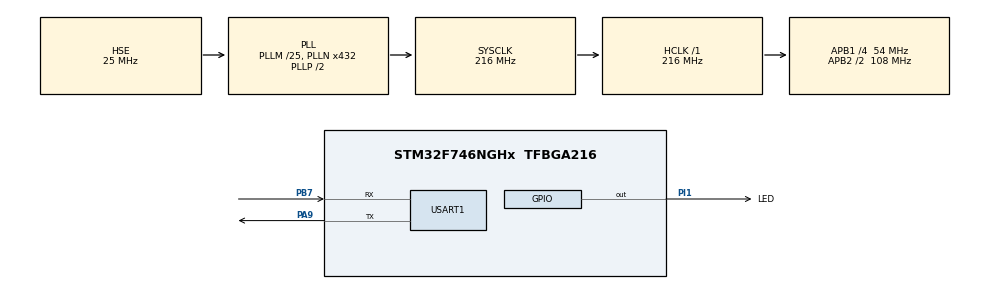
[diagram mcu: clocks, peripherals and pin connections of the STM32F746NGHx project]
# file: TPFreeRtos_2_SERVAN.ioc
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FREERTOS.Tasks01=defaultTask,0,128,StartDefaultTask,Default,NULL,Dynamic,NULL,NULL
FREERTOS.configTOTAL_HEAP_SIZE=20000
FREERTOS.configUSE_NEWLIB_REENTRANT=1
Mcu.Family=STM32F7
Mcu.Name=STM32F746NGHx
Mcu.Package=TFBGA216
NVIC.PriorityGroup=NVIC_PRIORITYGROUP_4
NVIC.TIM6_DAC_IRQn=true\:15\:0\:false\:false\:true\:false\:false\:true\:true
NVIC.TimeBase=TIM6_DAC_IRQn
NVIC.TimeBaseIP=TIM6
NVIC.USART1_IRQn=true\:5\:0\:false\:false\:true\:true\:true\:true\:true
PA13.Mode=Serial_Wire
PA13.Signal=SYS_JTMS-SWDIO
PA14.Mode=Serial_Wire
PA14.Signal=SYS_JTCK-SWCLK
PA9.Mode=Asynchronous
PA9.Signal=USART1_TX
PB7.Mode=Asynchronous
PB7.Signal=USART1_RX
PH0/OSC_IN.Mode=HSE-External-Oscillator
PH0/OSC_IN.Signal=RCC_OSC_IN
PH1/OSC_OUT.Mode=HSE-External-Oscillator
PH1/OSC_OUT.Signal=RCC_OSC_OUT
PI1.GPIO_Label=LED
PI1.Signal=GPIO_Output
ProjectManager.HeapSize=0x200
ProjectManager.StackSize=0x400
ProjectManager.TargetToolchain=STM32CubeIDE
RCC.AHBFreq_Value=216000000
RCC.APB1CLKDivider=RCC_HCLK_DIV4
RCC.APB1Freq_Value=54000000
RCC.APB1TimFreq_Value=108000000
RCC.APB2CLKDivider=RCC_HCLK_DIV2
RCC.APB2Freq_Value=108000000
RCC.APB2TimFreq_Value=216000000
RCC.CortexFreq_Value=216000000
RCC.HCLKFreq_Value=216000000
RCC.HSE_VALUE=25000000
RCC.HSI_VALUE=16000000
RCC.LSE_VALUE=32768
RCC.PLLM=25
RCC.PLLN=432
RCC.PLLSourceVirtual=RCC_PLLSOURCE_HSE
RCC.SYSCLKFreq_VALUE=216000000
RCC.SYSCLKSource=RCC_SYSCLKSOURCE_PLLCLK
RCC.USBFreq_Value=216000000
RCC.VCOOutputFreq_Value=432000000
USART1.VirtualMode-Asynchronous=VM_ASYNC
VP_FREERTOS_VS_CMSIS_V1.Mode=CMSIS_V1
VP_SYS_VS_tim6.Mode=TIM6
board=STM32F746G-DISCO

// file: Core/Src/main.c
/* USER CODE BEGIN Header */
/**
 ******************************************************************************
 * @file           : main.c
 * @brief          : Main program body
 ******************************************************************************
 * @attention
 *
 * Copyright (c) 2023 STMicroelectronics.
 * All rights reserved.
 *
 * This software is licensed under terms that can be found in the LICENSE file
 * in the root directory of this software component.
 * If no LICENSE file comes with this software, it is provided AS-IS.
 *
 ******************************************************************************
 */
/* USER CODE END Header */
#include "main.h"
#include "cmsis_os.h"
#include "usart.h"
#include "gpio.h"

/* USER CODE BEGIN Includes */
#include <stdio.h>
#include <stdlib.h>
#include "shell.h"
/* USER CODE END Includes */

/* USER CODE BEGIN PD */
#define TASK_SHELL_STACK_LENGHT 512
#define TASK_SHELL_PRIORITY 1
/* USER CODE END PD */

void SystemClock_Config(void);
void MX_FREERTOS_Init(void);

/* USER CODE BEGIN 0 */
int __io_putchar(int ch)
{
	HAL_UART_Transmit(&huart1, (uint8_t*)&ch, 1, HAL_MAX_DELAY);

	return ch;
}

int fonction(int argc, char ** argv)
{
	for (int i=0;i<argc;i++)
	{
		printf("l'argument %d est : %s\r\n",i,argv[i]);
	}

	return 0;
}

int addition(int argc, char ** argv)
{
	if (argc ==3)
	{
		int a,b;

		a=atoi(argv[1]);
		b=atoi(argv[2]);
		printf("La somme est %d\r\n",a+b);
	}
	else
	{
		printf("Erreur, il n'y a pas le bon nombre d'argument\r\n");
	}
	return 0;
}

void HAL_UART_RxCpltCallback(UART_HandleTypeDef *huart){

	if(huart -> Instance == USART1)
	{
		shell_uart_receive_irq_cb();
	}
}

void task_shell(void * unused){
	shell_init();
	shell_add('f', fonction, "Une fonction inutile");
	shell_add('a', addition, "Une fonction qui fait la somme");
	shell_run();
	//shell run est une fct infinie on ne sort pas de la tache
}
/* USER CODE END 0 */

int main(void)
{

	/* MCU Configuration--------------------------------------------------------*/

	/* Reset of all peripherals, Initializes the Flash interface and the Systick. */
	HAL_Init();

	/* Configure the system clock */
	SystemClock_Config();

	/* Initialize all configured peripherals */
	MX_GPIO_Init();
	MX_USART1_UART_Init();
	/* USER CODE BEGIN 2 */
	BaseType_t ret;
	TaskHandle_t h_task_shell =NULL;

	ret = xTaskCreate(task_shell, "Shell", TASK_SHELL_STACK_LENGHT, NULL, TASK_SHELL_PRIORITY, &h_task_shell);

	if (ret != pdPASS)
	{
		printf("impossible de créer la teche shell\r\n");
	}

	vTaskStartScheduler();
	/* USER CODE END 2 */

	/* Call init function for freertos objects (in freertos.c) */
	MX_FREERTOS_Init();

	/* Start scheduler */
	osKernelStart();

	/* We should never get here as control is now taken by the scheduler */
	/* Infinite loop */
	while (1)
	{

	}
}

void SystemClock_Config(void)
{
	RCC_OscInitTypeDef RCC_OscInitStruct = {0};
	RCC_ClkInitTypeDef RCC_ClkInitStruct = {0};

	/** Configure the main internal regulator output voltage
	 */
	__HAL_RCC_PWR_CLK_ENABLE();
	__HAL_PWR_VOLTAGESCALING_CONFIG(PWR_REGULATOR_VOLTAGE_SCALE1);

	/** Initializes the RCC Oscillators according to the specified parameters
	 * in the RCC_OscInitTypeDef structure.
	 */
	RCC_OscInitStruct.OscillatorType = RCC_OSCILLATORTYPE_HSE;
	RCC_OscInitStruct.HSEState = RCC_HSE_ON;
	RCC_OscInitStruct.PLL.PLLState = RCC_PLL_ON;
	RCC_OscInitStruct.PLL.PLLSource = RCC_PLLSOURCE_HSE;
	RCC_OscInitStruct.PLL.PLLM = 25;
	RCC_OscInitStruct.PLL.PLLN = 432;
	RCC_OscInitStruct.PLL.PLLP = RCC_PLLP_DIV2;
	RCC_OscInitStruct.PLL.PLLQ = 2;
	if (HAL_RCC_OscConfig(&RCC_OscInitStruct) != HAL_OK)
	{
		Error_Handler();
	}

	/** Activate the Over-Drive mode
	 */
	if (HAL_PWREx_EnableOverDrive() != HAL_OK)
	{
		Error_Handler();
	}

	/** Initializes the CPU, AHB and APB buses clocks
	 */
	RCC_ClkInitStruct.ClockType = RCC_CLOCKTYPE_HCLK|RCC_CLOCKTYPE_SYSCLK
			|RCC_CLOCKTYPE_PCLK1|RCC_CLOCKTYPE_PCLK2;
	RCC_ClkInitStruct.SYSCLKSource = RCC_SYSCLKSOURCE_PLLCLK;
	RCC_ClkInitStruct.AHBCLKDivider = RCC_SYSCLK_DIV1;
	RCC_ClkInitStruct.APB1CLKDivider = RCC_HCLK_DIV4;
	RCC_ClkInitStruct.APB2CLKDivider = RCC_HCLK_DIV2;

	if (HAL_RCC_ClockConfig(&RCC_ClkInitStruct, FLASH_LATENCY_7) != HAL_OK)
	{
		Error_Handler();
	}
}

void HAL_TIM_PeriodElapsedCallback(TIM_HandleTypeDef *htim)
{
	if (htim->Instance == TIM6) {
		HAL_IncTick();
	}
}

void Error_Handler(void)
{
	__disable_irq();
	while (1)
	{
	}
}
